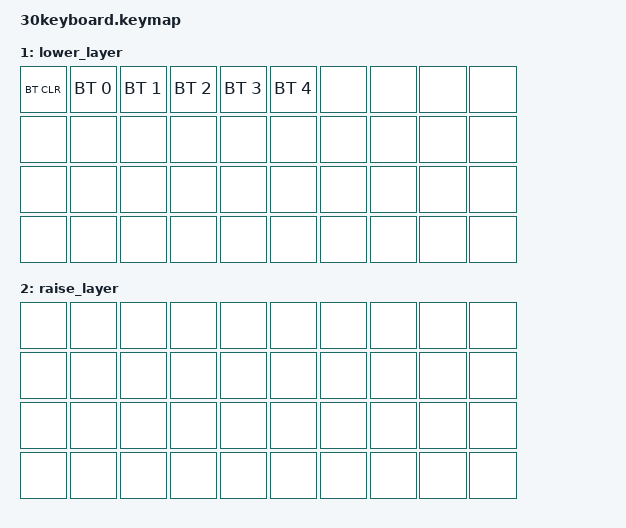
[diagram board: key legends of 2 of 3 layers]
#include <behaviors.dtsi>
#include <dt-bindings/zmk/keys.h>
#include <dt-bindings/zmk/bt.h>

/ {
    keymap {
        compatible = "zmk,keymap";

        default_layer {
            bindings = <
                &kp ESC   &kp Q     &kp W     &kp E     &kp R     &kp T     &kp Y     &kp U     &kp I     &kp O
                &kp TAB   &kp A     &kp S     &kp D     &kp F     &kp G     &kp H     &kp J     &kp ENTER
                &kp LSHFT &kp Z     &kp X     &kp C     &kp V     &kp B     &kp N     &kp RSHFT &mo 1
                &kp LCTRL &kp LGUI  &kp LALT  &kp SPACE &kp SPACE &kp AT    &kp MINUS &mo 2
            >;
        };

        lower_layer {
            bindings = <
                &bt BT_CLR &bt BT_SEL 0 &bt BT_SEL 1 &bt BT_SEL 2 &bt BT_SEL 3 &bt BT_SEL 4 &none &none &none &none
                &none      &none        &none        &none        &none        &none        &none &none &none &none
                &none      &none        &none        &none        &none        &none        &none &none &none &none
                &none      &none        &none        &none        &none        &none        &none &none &none &none
            >;
        };

        raise_layer {
            bindings = <
                &none &none &none &none &none &none &none &none &none &none
                &none &none &none &none &none &none &none &none &none &none
                &none &none &none &none &none &none &none &none &none &none
                &none &none &none &none &none &none &none &none &none &none
            >;
        };
    };
};
